# AT32F403Axx register map
Vendor: Keil; Series: AT32F403A; File version: 1.0
CPU: CM4 r0p1, little endian, no MPU, FPU, 4 interrupt priority bits
Registers are 32-bit, read-write, reset 0x0 unless marked. A register's access mark holds for its fields unless they carry their own. Offsets are from the block's base; [hi:lo] are bit positions; {n}, {i} and the like mark numbered series.

## AFIO — Alternate function I/O
Base 0x40010000
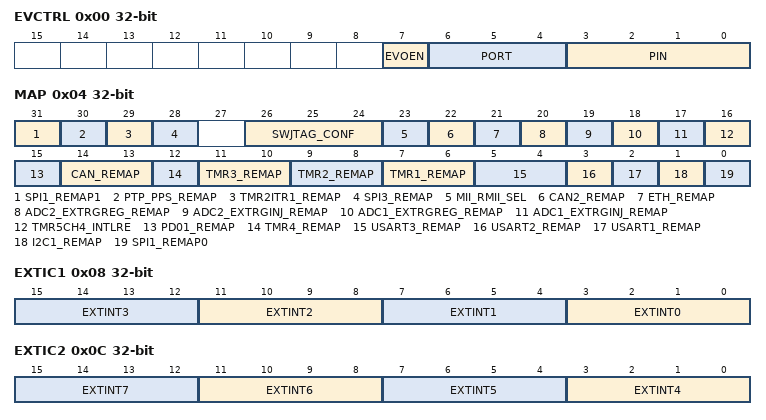
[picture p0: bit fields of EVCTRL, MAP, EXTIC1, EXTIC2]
0x00 EVCTRL — Event Control Register (AFIO_EVCTRL)
  [7] EVOEN — Event Output Enable
  [6:4] PORT — Port selection
  [3:0] PIN — Pin selection
0x04 MAP — AF remap and debug I/O configuration register (AFIO_MAP)
  [31] SPI1_REMAP1 — SPI1 remapping bit1
  [30] PTP_PPS_REMAP — PTP_PPS remapping
  [29] TMR2ITR1_REMAP — TMR2ITR1 remapping
  [28] SPI3_REMAP — SPI3 remapping
  [26:24] SWJTAG_CONF — Serial wire JTAG configuration
  [23] MII_RMII_SEL — MII_RMII select
  [22] CAN2_REMAP — CAN2 remapping
  [21] ETH_REMAP — Ethmac remapping
  [20] ADC2_EXTRGREG_REMAP — ADC 2 external trigger regular conversion remapping
  [19] ADC2_EXTRGINJ_REMAP — ADC 2 external trigger injected conversion remapping
  [18] ADC1_EXTRGREG_REMAP — ADC 1 external trigger regular conversion remapping
  [17] ADC1_EXTRGINJ_REMAP — ADC 1 External trigger injected conversion remapping
  [16] TMR5CH4_INTLRE — Set and cleared by software
  [15] PD01_REMAP — Port D0/Port D1 mapping on OSCIN/OSCOUT
  [14:13] CAN_REMAP — CAN1 remapping
  [12] TMR4_REMAP — TIM4 remapping
  [11:10] TMR3_REMAP — TIM3 remapping
  [9:8] TMR2_REMAP — TIM2 remapping
  [7:6] TMR1_REMAP — TIM1 remapping
  [5:4] USART3_REMAP — USART3 remapping
  [3] USART2_REMAP — USART2 remapping
  [2] USART1_REMAP — USART1 remapping
  [1] I2C1_REMAP — I2C1 remapping
  [0] SPI1_REMAP0 — SPI1 remapping bit0
0x08 EXTIC1 — External interrupt configuration register 1 (AFIO_EXTIC1)
  [4n+3:4n] EXTINT{n} (n=0..3) — EXTI{n} configuration
0x0C EXTIC2 — External interrupt configuration register 2 (AFIO_EXTIC2)
  [4n-13:4n-16] EXTINT{n} (n=4..7) — EXTI{n} configuration
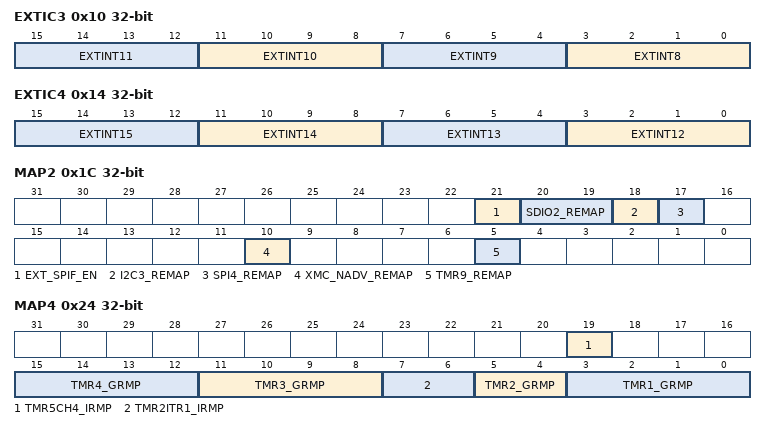
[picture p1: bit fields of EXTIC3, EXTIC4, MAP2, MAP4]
0x10 EXTIC3 — External interrupt configuration register 3 (AFIO_EXTIC3)
  [4n-29:4n-32] EXTINT{n} (n=8..11) — EXTI{n} configuration
0x14 EXTIC4 — External interrupt configuration register 4 (AFIO_EXTIC4)
  [4n-45:4n-48] EXTINT{n} (n=12..15) — EXTI{n} configuration
0x1C MAP2 — AF remap and debug I/O configuration register
  [21] EXT_SPIF_EN — Enable ExtSPIFlash
  [20:19] SDIO2_REMAP — SDIO2 remapping
  [18] I2C3_REMAP — I2C3 remapping
  [17] SPI4_REMAP — SPI4 remapping
  [10] XMC_NADV_REMAP — NADV connect/disconnect
  [5] TMR9_REMAP — TIM9 remapping
0x20 MAP3 — AF remap and debug I/O configuration register
  [3:0] TMR9_GRMP — TIM9 remapping
0x24 MAP4 — AF remap and debug I/O configuration register
  [19] TMR5CH4_IRMP — TMR5 channel4 internal remap
  [15:12] TMR4_GRMP — TIM4 remapping
  [11:8] TMR3_GRMP — TIM3 remapping
  [7:6] TMR2ITR1_IRMP — TIM2_ITR1 remapping
  [5:4] TMR2_GRMP — TIM2 remapping
  [3:0] TMR1_GRMP — TIM1 remapping
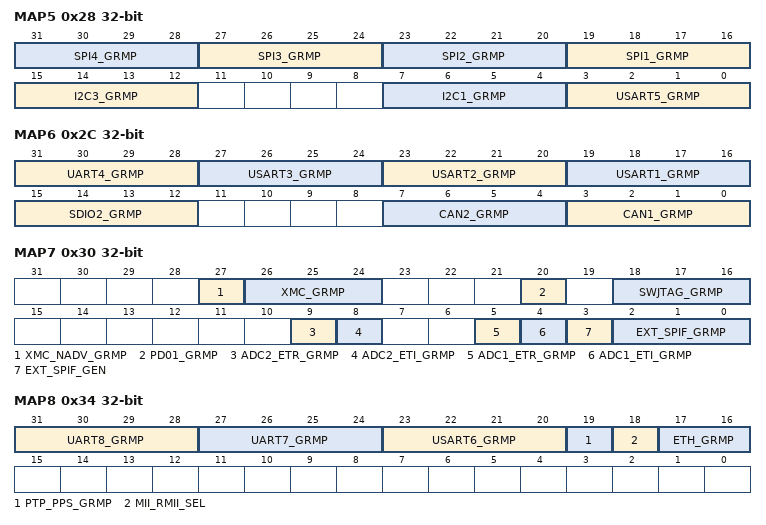
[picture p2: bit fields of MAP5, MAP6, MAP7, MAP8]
0x28 MAP5 — AF remap and debug I/O configuration register
  [4n+15:4n+12] SPI{n}_GRMP (n=1..4) — SPI{n} remapping
  [15:12] I2C3_GRMP — I2C3 remapping
  [7:4] I2C1_GRMP — I2C1 remapping
  [3:0] USART5_GRMP — USART5 remapping
0x2C MAP6 — AF remap and debug I/O configuration register
  [31:28] UART4_GRMP — UART4 remapping
  [27:24] USART3_GRMP — USART3 remapping
  [23:20] USART2_GRMP — USART2 remapping
  [19:16] USART1_GRMP — USART1 remapping
  [15:12] SDIO2_GRMP — SDIO remapping
  [7:4] CAN2_GRMP — CAN2 remapping
  [3:0] CAN1_GRMP — CAN1 remapping
0x30 MAP7 — AF remap and debug I/O configuration register
  [27] XMC_NADV_GRMP — XMC_NADV remapping
  [26:24] XMC_GRMP — XMC remapping
  [20] PD01_GRMP — PortD0/PortD1 mappingon OSC_IN/OSC_OUT
  [18:16] SWJTAG_GRMP — Serial wire JTAG remapping
  [9] ADC2_ETR_GRMP — ADC2 external trigger regular conversion remapping
  [8] ADC2_ETI_GRMP — ADC2 external trigger injected conversion remapping
  [5] ADC1_ETR_GRMP — ADC1 external trigger regular conversion remapping
  [4] ADC1_ETI_GRMP — ADC1 External trigger injected conversion remapping
  [3] EXT_SPIF_GEN — External SPI Flash enable
  [2:0] EXT_SPIF_GRMP — External SPI Flash remapping
0x34 MAP8 — AF remap and debug I/O configuration register
  [31:28] UART8_GRMP — UART8 remapping
  [27:24] UART7_GRMP — UART7 remapping
  [23:20] USART6_GRMP — USART6 remapping
  [19] PTP_PPS_GRMP — PTP_PPS remapping
  [18] MII_RMII_SEL — MII_RMII select
  [17:16] ETH_GRMP — ETH remapping
